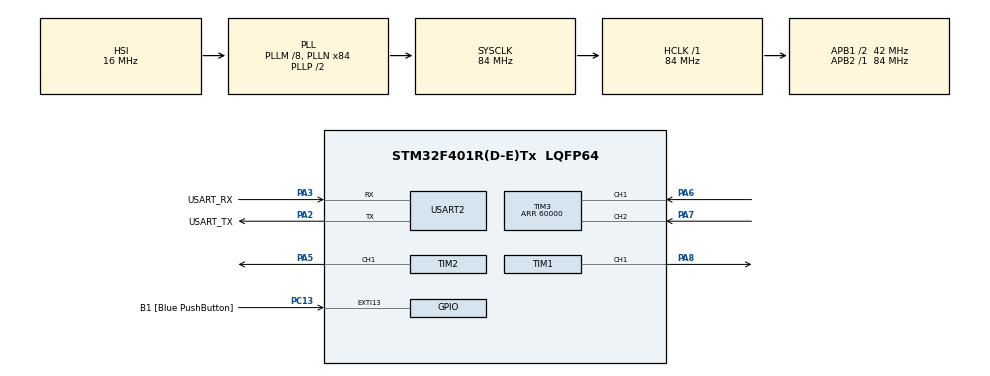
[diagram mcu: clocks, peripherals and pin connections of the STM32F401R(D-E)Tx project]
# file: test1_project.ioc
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Mcu.Family=STM32F4
Mcu.Name=STM32F401R(D-E)Tx
Mcu.Package=LQFP64
NVIC.PriorityGroup=NVIC_PRIORITYGROUP_0
PA13.GPIO_Label=TMS
PA13.Mode=Serial_Wire
PA13.Signal=SYS_JTMS-SWDIO
PA14.GPIO_Label=TCK
PA14.Mode=Serial_Wire
PA14.Signal=SYS_JTCK-SWCLK
PA2.GPIO_Label=USART_TX
PA2.GPIO_Mode=GPIO_MODE_AF_PP
PA2.GPIO_PuPd=GPIO_NOPULL
PA2.GPIO_Speed=GPIO_SPEED_FREQ_LOW
PA2.Mode=Asynchronous
PA2.Signal=USART2_TX
PA3.GPIO_Label=USART_RX
PA3.GPIO_Mode=GPIO_MODE_AF_PP
PA3.GPIO_PuPd=GPIO_NOPULL
PA3.GPIO_Speed=GPIO_SPEED_FREQ_LOW
PA3.Mode=Asynchronous
PA3.Signal=USART2_RX
PA5.Signal=S_TIM2_CH1_ETR
PA6.GPIO_PuPd=GPIO_PULLUP
PA6.Signal=S_TIM3_CH1
PA7.GPIO_PuPd=GPIO_PULLUP
PA7.Signal=S_TIM3_CH2
PA8.Signal=S_TIM1_CH1
PB3.GPIO_Label=SWO
PB3.Signal=SYS_JTDO-SWO
PC13-ANTI_TAMP.GPIO_Label=B1 [Blue PushButton]
PC13-ANTI_TAMP.GPIO_ModeDefaultEXTI=GPIO_MODE_IT_FALLING
PC13-ANTI_TAMP.GPIO_PuPd=GPIO_NOPULL
PC13-ANTI_TAMP.Signal=GPXTI13
PC14-OSC32_IN.Mode=LSE-External-Oscillator
PC14-OSC32_IN.Signal=RCC_OSC32_IN
PC15-OSC32_OUT.Mode=LSE-External-Oscillator
PC15-OSC32_OUT.Signal=RCC_OSC32_OUT
PH0\ -\ OSC_IN.Mode=HSE-External-Clock-Source
PH0\ -\ OSC_IN.Signal=RCC_OSC_IN
PH1\ -\ OSC_OUT.Mode=HSE-External-Clock-Source
PH1\ -\ OSC_OUT.Signal=RCC_OSC_OUT
ProjectManager.HeapSize=0x200
ProjectManager.StackSize=0x400
ProjectManager.TargetToolchain=TrueSTUDIO
RCC.48MHZClocksFreq_Value=24000000
RCC.AHBFreq_Value=84000000
RCC.APB1CLKDivider=RCC_HCLK_DIV2
RCC.APB1Freq_Value=42000000
RCC.APB1TimFreq_Value=84000000
RCC.APB2Freq_Value=84000000
RCC.APB2TimFreq_Value=84000000
RCC.CortexFreq_Value=84000000
RCC.HCLKFreq_Value=84000000
RCC.HSE_VALUE=8000000
RCC.HSI_VALUE=16000000
RCC.PLLM=8
RCC.PLLN=84
RCC.PLLQ=7
RCC.SYSCLKFreq_VALUE=84000000
RCC.SYSCLKSource=RCC_SYSCLKSOURCE_PLLCLK
RCC.VCOOutputFreq_Value=168000000
SH.S_TIM1_CH1.0=TIM1_CH1,PWM Generation1 CH1
SH.S_TIM2_CH1_ETR.0=TIM2_CH1,PWM Generation1 CH1
SH.S_TIM3_CH1.0=TIM3_CH1,Encoder_Interface
SH.S_TIM3_CH2.0=TIM3_CH2,Encoder_Interface
TIM1.Channel-PWM\ Generation1\ CH1=TIM_CHANNEL_1
TIM1.Period=1000
TIM1.Prescaler=4
TIM11.Period=1000
TIM11.Prescaler=84
TIM2.Channel-PWM\ Generation1\ CH1=TIM_CHANNEL_1
TIM2.Period=1000
TIM2.Prescaler=4
TIM3.EncoderMode=TIM_ENCODERMODE_TI12
TIM3.IC1Filter=8
TIM3.IC2Filter=8
TIM3.Period=60000
USART2.VirtualMode=VM_ASYNC
VP_TIM11_VS_ClockSourceINT.Mode=Enable_Timer
VP_TIM1_VS_ClockSourceINT.Mode=Internal
board=NUCLEO-F401RE

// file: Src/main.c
/* USER CODE BEGIN Header */
/**
  ******************************************************************************
  * @file           : main.c
  * @brief          : Main program body
  ******************************************************************************
  ** This notice applies to any and all portions of this file
  * that are not between comment pairs USER CODE BEGIN and
  * USER CODE END. Other portions of this file, whether
  * inserted by the user or by software development tools
  * are owned by their respective copyright owners.
  *
  * COPYRIGHT(c) 2019 STMicroelectronics
  *
  * Redistribution and use in source and binary forms, with or without modification,
  * are permitted provided that the following conditions are met:
  *   1. Redistributions of source code must retain the above copyright notice,
  *      this list of conditions and the following disclaimer.
  *   2. Redistributions in binary form must reproduce the above copyright notice,
  *      this list of conditions and the following disclaimer in the documentation
  *      and/or other materials provided with the distribution.
  *   3. Neither the name of STMicroelectronics nor the names of its contributors
  *      may be used to endorse or promote products derived from this software
  *      without specific prior written permission.
  *
  * THIS SOFTWARE IS PROVIDED BY THE COPYRIGHT HOLDERS AND CONTRIBUTORS "AS IS"
  * AND ANY EXPRESS OR IMPLIED WARRANTIES, INCLUDING, BUT NOT LIMITED TO, THE
  * IMPLIED WARRANTIES OF MERCHANTABILITY AND FITNESS FOR A PARTICULAR PURPOSE ARE
  * DISCLAIMED. IN NO EVENT SHALL THE COPYRIGHT HOLDER OR CONTRIBUTORS BE LIABLE
  * FOR ANY DIRECT, INDIRECT, INCIDENTAL, SPECIAL, EXEMPLARY, OR CONSEQUENTIAL
  * DAMAGES (INCLUDING, BUT NOT LIMITED TO, PROCUREMENT OF SUBSTITUTE GOODS OR
  * SERVICES; LOSS OF USE, DATA, OR PROFITS; OR BUSINESS INTERRUPTION) HOWEVER
  * CAUSED AND ON ANY THEORY OF LIABILITY, WHETHER IN CONTRACT, STRICT LIABILITY,
  * OR TORT (INCLUDING NEGLIGENCE OR OTHERWISE) ARISING IN ANY WAY OUT OF THE USE
  * OF THIS SOFTWARE, EVEN IF ADVISED OF THE POSSIBILITY OF SUCH DAMAGE.
  *
  ******************************************************************************
  */
/* USER CODE END Header */

#include "main.h"
#include "tim.h"
#include "usart.h"
#include "gpio.h"

/* USER CODE BEGIN Includes */
#include <string.h>
/* USER CODE END Includes */

void SystemClock_Config(void);

int main(void)
{

  /* MCU Configuration--------------------------------------------------------*/

  /* Reset of all peripherals, Initializes the Flash interface and the Systick. */
  HAL_Init();

  /* Configure the system clock */
  SystemClock_Config();

  /* Initialize all configured peripherals */
  MX_GPIO_Init();
  MX_USART2_UART_Init();
  MX_TIM1_Init();
  MX_TIM2_Init();
  MX_TIM3_Init();
  MX_TIM11_Init();
  /* USER CODE BEGIN 2 */
  HAL_TIM_PWM_Start(&htim2, TIM_CHANNEL_1);  // sa ovim startujes tajmer

  __HAL_TIM_SET_COMPARE(&htim2, TIM_CHANNEL_1, 0);

  while(HAL_GPIO_ReadPin(B1_GPIO_Port,B1_Pin));
  __HAL_TIM_SET_COMPARE(&htim2, TIM_CHANNEL_1, 100);
  HAL_Delay(200);

  while(HAL_GPIO_ReadPin(B1_GPIO_Port,B1_Pin));
  __HAL_TIM_SET_COMPARE(&htim2, TIM_CHANNEL_1, 1000);

  //Encoder
  HAL_TIM_Encoder_Start(&htim3, TIM_CHANNEL_1);
  HAL_TIM_Encoder_Start(&htim3, TIM_CHANNEL_2);

  /* USER CODE END 2 */

  /* Infinite loop */
  /* USER CODE BEGIN WHILE */
  while (1)
  {
	  char p[20] = "";

	  snprintf(p, sizeof(p), "%d\n\r", __HAL_TIM_GET_COUNTER(&htim3));

	  HAL_UART_Transmit(&huart2, p, strlen(p),10);
	  HAL_Delay(100);
    /* USER CODE END WHILE */

  }
}

void SystemClock_Config(void)
{
  RCC_OscInitTypeDef RCC_OscInitStruct = {0};
  RCC_ClkInitTypeDef RCC_ClkInitStruct = {0};

  /**Configure the main internal regulator output voltage
  */
  __HAL_RCC_PWR_CLK_ENABLE();
  __HAL_PWR_VOLTAGESCALING_CONFIG(PWR_REGULATOR_VOLTAGE_SCALE2);
  /**Initializes the CPU, AHB and APB busses clocks
  */
  RCC_OscInitStruct.OscillatorType = RCC_OSCILLATORTYPE_HSI;
  RCC_OscInitStruct.HSIState = RCC_HSI_ON;
  RCC_OscInitStruct.HSICalibrationValue = RCC_HSICALIBRATION_DEFAULT;
  RCC_OscInitStruct.PLL.PLLState = RCC_PLL_ON;
  RCC_OscInitStruct.PLL.PLLSource = RCC_PLLSOURCE_HSI;
  RCC_OscInitStruct.PLL.PLLM = 8;
  RCC_OscInitStruct.PLL.PLLN = 84;
  RCC_OscInitStruct.PLL.PLLP = RCC_PLLP_DIV2;
  RCC_OscInitStruct.PLL.PLLQ = 7;
  if (HAL_RCC_OscConfig(&RCC_OscInitStruct) != HAL_OK)
  {
    Error_Handler();
  }
  /**Initializes the CPU, AHB and APB busses clocks
  */
  RCC_ClkInitStruct.ClockType = RCC_CLOCKTYPE_HCLK|RCC_CLOCKTYPE_SYSCLK
                              |RCC_CLOCKTYPE_PCLK1|RCC_CLOCKTYPE_PCLK2;
  RCC_ClkInitStruct.SYSCLKSource = RCC_SYSCLKSOURCE_PLLCLK;
  RCC_ClkInitStruct.AHBCLKDivider = RCC_SYSCLK_DIV1;
  RCC_ClkInitStruct.APB1CLKDivider = RCC_HCLK_DIV2;
  RCC_ClkInitStruct.APB2CLKDivider = RCC_HCLK_DIV1;

  if (HAL_RCC_ClockConfig(&RCC_ClkInitStruct, FLASH_LATENCY_2) != HAL_OK)
  {
    Error_Handler();
  }
}

void Error_Handler(void)
{
}

/************************ (C) COPYRIGHT STMicroelectronics *****END OF FILE****/
